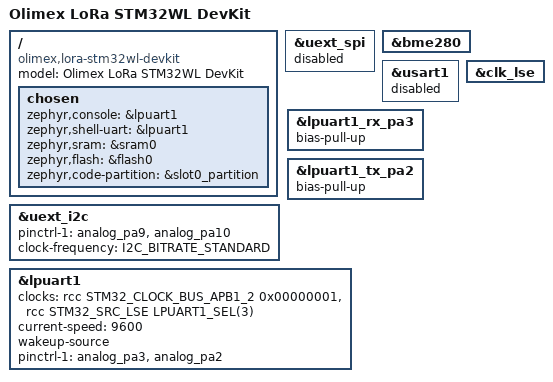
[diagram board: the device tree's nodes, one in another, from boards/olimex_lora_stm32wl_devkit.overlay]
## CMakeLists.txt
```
# SPDX-License-Identifier: Apache-2.0

cmake_minimum_required(VERSION 3.20.0)

find_package(Zephyr REQUIRED HINTS $ENV{ZEPHYR_BASE})
project(helium_meteo)

target_sources(                             app PRIVATE src/main.c)
target_sources_ifdef(CONFIG_SETTINGS        app PRIVATE src/nvm.c)
target_sources_ifdef(CONFIG_SHELL           app PRIVATE src/shell.c)
```

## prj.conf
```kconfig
# SPDX-License-Identifier: Apache-2.0

CONFIG_LOG=y
CONFIG_SPI=y
CONFIG_GPIO=y
CONFIG_LORA=y
CONFIG_LORA_STM32WL_SUBGHZ_RADIO=y
CONFIG_LORAWAN=y
CONFIG_LORAMAC_REGION_EU868=y
CONFIG_LORAWAN_SYSTEM_MAX_RX_ERROR=200
CONFIG_MAIN_STACK_SIZE=2048
CONFIG_SYSTEM_WORKQUEUE_STACK_SIZE=2048
CONFIG_FLASH_MAP=y
CONFIG_FLASH=y
CONFIG_SETTINGS=y
CONFIG_NVS=y

CONFIG_SERIAL=y
CONFIG_CONSOLE=y
CONFIG_UART_CONSOLE=y
CONFIG_UART_LINE_CTRL=y

# Shell
CONFIG_SHELL=y
CONFIG_DATE_SHELL=y
CONFIG_POSIX_TIMERS=y
CONFIG_SHELL_BACKEND_DUMMY=y

# Logging
CONFIG_LOG_PROCESS_THREAD_STACK_SIZE=1024

# OS
CONFIG_REBOOT=y
CONFIG_HEAP_MEM_POOL_SIZE=2048

# Power
CONFIG_PM=y
CONFIG_PM_DEVICE=y
CONFIG_PM_DEVICE_RUNTIME=y


# BME280 Sensor.
CONFIG_SENSOR=y
CONFIG_SENSOR_SHELL=y
CONFIG_BME280=y
CONFIG_BME280_MODE_FORCED=y
CONFIG_BME280_TEMP_OVER_4X=y
CONFIG_BME280_PRESS_OVER_4X=y
CONFIG_BME280_HUMIDITY_OVER_4X=y
```

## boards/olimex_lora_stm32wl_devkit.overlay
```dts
#include <zephyr/dt-bindings/pinctrl/stm32-pinctrl.h>

/ {
        model = "Olimex LoRa STM32WL DevKit";
        compatible = "olimex,lora-stm32wl-devkit";

        chosen {
                zephyr,console = &lpuart1;
                zephyr,shell-uart = &lpuart1;
                zephyr,sram = &sram0;
                zephyr,flash = &flash0;
                zephyr,code-partition = &slot0_partition;
        };

};

&uext_spi {
	status = "disabled";
};

&bme280 {
	status = "okay";
};

&usart1 {
	status = "disabled";
};

#if 0
&pinctrl {
	powerdown_pa9: powerdown_pa9 {
		pinmux = <STM32_PINMUX('A', 9, GPIO)>;
		output-high;
		bias-disable;
	};
	powerdown_pa10: powerdown_pa10{
		pinmux = <STM32_PINMUX('A', 10, GPIO)>;
		output-high;
		bias-disable;
	};
};
#endif

&uext_i2c {
	pinctrl-1 = <&analog_pa9 &analog_pa10>;
	pinctrl-names = "default", "sleep";
	clock-frequency = <I2C_BITRATE_STANDARD>;

	status = "okay";
};

&lpuart1_rx_pa3 {
	bias-pull-up;
};

&lpuart1_tx_pa2 {
	bias-pull-up;
};

&lpuart1 {
        clocks = <&rcc STM32_CLOCK_BUS_APB1_2 0x00000001>,
                <&rcc STM32_SRC_LSE LPUART1_SEL(3)>;

	current-speed = <9600>;

	wakeup-source;

        /* Configure sleep pinctrl configuration which will be used when
         * device is not configured as wakeup source by the application.
         * This use case is only applicable in PM_DEVICE mode.
         */
        pinctrl-1 = <&analog_pa3 &analog_pa2>;
        pinctrl-names = "default", "sleep";

};


&clk_lse {
	status = "okay";
};
```

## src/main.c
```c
/*
 *
 * SPDX-License-Identifier: Apache-2.0
 */

#include <stdio.h>
#include <stdlib.h>
#include <zephyr/device.h>
#include <zephyr/drivers/sensor.h>
#include <zephyr/drivers/gpio.h>
#include <zephyr/lorawan/lorawan.h>
#include <zephyr/kernel.h>
#include <zephyr/sys/reboot.h>
#include <zephyr/sys/printk.h>
#include <zephyr/pm/device.h>
#include <zephyr/pm/policy.h>


#include "lorawan_config.h"
#if IS_ENABLED(CONFIG_ADC)
#include "battery.h"
#endif
#include "nvm.h"
#if IS_ENABLED(CONFIG_SHELL)
#include "shell.h"
#endif

#define LOG_LEVEL CONFIG_LOG_DEFAULT_LEVEL
#include <zephyr/logging/log.h>
LOG_MODULE_REGISTER(helium_meteo);

/*
 * A build error on this line means your board is unsupported.
 * See the sample documentation for information on how to fix this.
 */
static const struct gpio_dt_spec dt_led0 = GPIO_DT_SPEC_GET(DT_ALIAS(led0), gpios);
static const struct gpio_dt_spec dt_sw0 = GPIO_DT_SPEC_GET(DT_ALIAS(sw0), gpios);
static struct gpio_callback user_button_cb_data;

const struct device *const dev_console = DEVICE_DT_GET(DT_CHOSEN(zephyr_console));


struct s_lorawan_config lorawan_config = {
	.dev_eui = { 0x00, 0x01, 0x02, 0x03, 0x04, 0x05, 0x06, 0x07 },
	.app_eui = { 0x00, 0x01, 0x02, 0x03, 0x04, 0x05, 0x06, 0x07 },
	.app_key = { 0x00, 0x01, 0x02, 0x03, 0x04, 0x05, 0x06, 0x07, 0x08, 0x09, 0x0A, 0x0B, 0x0C, 0x0D, 0x0E, 0x0F },
	.lora_mode = LORAWAN_ACT_OTAA,
	.data_rate = LORAWAN_DR_3,
	.lora_class = LORAWAN_CLASS_A,
	.confirmed_msg = LORAWAN_MSG_UNCONFIRMED,
	.app_port = 2,
	.auto_join = false,
	.send_repeat_time = 3600 / 2,
	/* max join attempt in one join session */
	.join_try_count = 5,
	/* max join sessions before give up and reboot. 20 * 5 = 100 join attempts */
	.max_join_retry_sessions_count = 20,
	/* max join session interval in sec */
	.join_try_interval = 300,
	.max_inactive_time_window = 2 * 3600,
	.max_failed_msg = 120,
};

struct s_status lorawan_status = {
	.joined = false,
	.msgs_sent = 0,
	.msgs_failed = 0,
	.msgs_failed_total = 0,
	.join_retry_sessions_count = 0,
};

struct s_meteo_data meteo_data;
char *data_ptr = (char*)&meteo_data;

#define LORA_JOIN_THREAD_STACK_SIZE 1500
#define LORA_JOIN_THREAD_PRIORITY 10
K_KERNEL_STACK_MEMBER(lora_join_thread_stack, LORA_JOIN_THREAD_STACK_SIZE);

struct s_helium_meteo_ctx {
	const struct device *lora_dev;
	const struct device *meteo_dev;
	struct k_timer send_timer;
	struct k_timer lora_join_timer;
	struct k_thread thread;
	struct k_sem lora_join_sem;
};

struct s_helium_meteo_ctx g_ctx;

enum lorawan_state_e {
	NOT_JOINED,
	JOINED,
};

/* Event queue. */

enum evt_t {
	EV_TIMER,
	EV_BUTTON,
	EV_SEND_DATA,
};

struct app_evt_t {
	enum evt_t event_type;
};

K_MSGQ_DEFINE(event_msgq, sizeof(struct app_evt_t), 10, 1);


static void update_send_timer(struct s_helium_meteo_ctx *ctx)
{
	uint32_t time = lorawan_config.send_repeat_time;

	if (time) {
		LOG_INF("Send interval timer start for %d sec", time);
		k_timer_start(&ctx->send_timer,
				K_SECONDS(time),
				K_SECONDS(time));
	}
}

static void send_timer_handler(struct k_timer *timer)
{
	struct app_evt_t ev;

	LOG_INF("Timer handler");

	ev.event_type = EV_TIMER;
	while (k_msgq_put(&event_msgq, &ev, K_NO_WAIT) != 0) {
		/* message queue is full: purge old data & try again */
		k_msgq_purge(&event_msgq);
	}
}

static void user_button_pressed(const struct device *dev, struct gpio_callback *cb,
                    uint32_t pins)
{
	struct app_evt_t ev;

	LOG_INF("Button handler");

	ev.event_type = EV_BUTTON;
	while (k_msgq_put(&event_msgq, &ev, K_NO_WAIT) != 0) {
		/* message queue is full: purge old data & try again */
		k_msgq_purge(&event_msgq);
	}
}


static int init_buttons(void)
{
	int err;

	if (!dt_sw0.port) {
		LOG_INF("User button not available");
		return -ENODEV;
	}
	if (!device_is_ready(dt_sw0.port)) {
		LOG_ERR("User button device not ready");
		return -ENODEV;
	}
	err = gpio_pin_configure_dt(&dt_sw0, GPIO_INPUT);
	if (err) {
		LOG_ERR("failed to configure user button gpio: %d", err);
		return err;
	}
	err = gpio_pin_interrupt_configure_dt(&dt_sw0, GPIO_INT_EDGE_TO_ACTIVE);
	if (err) {
		LOG_ERR("failed to configure user button gpio: %d", err);
		return err;
	}
	gpio_init_callback(&user_button_cb_data, user_button_pressed, BIT(dt_sw0.pin));
	gpio_add_callback(dt_sw0.port, &user_button_cb_data);

	return err;
}

static int init_leds(void)
{
	int err = 0;

	if (!dt_led0.port) {
		LOG_INF("LED0 not available");
		return -ENODEV;
	}
	if (!device_is_ready(dt_led0.port)) {
		LOG_ERR("LED0 device not ready");
		return -ENODEV;
	}
	/* Init led as output and turn it off */
	err = gpio_pin_configure_dt(&dt_led0, GPIO_OUTPUT_INACTIVE);
	if (err) {
		LOG_ERR("failed to configure LED0 gpio: %d", err);
		return err;
	}
	/* This is required to reach low-power modes. */
	err = gpio_pin_configure_dt(&dt_led0, GPIO_DISCONNECTED);

	return err;
}

static void led_enable(const struct gpio_dt_spec *led, int enable)
{
	if (led->port) {
		gpio_pin_set_dt(led, enable);
	}
}

static void dl_callback(uint8_t port, uint8_t flags, int16_t rssi, int8_t snr, uint8_t len,
			const uint8_t *data)
{
	LOG_INF("Port %d, Flags %x, RSSI %ddB, SNR %ddBm", port, flags, rssi, snr);
	if (data) {
		LOG_HEXDUMP_INF(data, len, "Payload: ");
	}
}

static struct lorawan_downlink_cb downlink_cb = {
	.port = LW_RECV_PORT_ANY,
	.cb = dl_callback
};

static void lorwan_datarate_changed(enum lorawan_datarate dr)
{
	uint8_t unused, max_size;

	lorawan_get_payload_sizes(&unused, &max_size);
	LOG_INF("New Datarate: DR_%d, Max Payload %d", dr, max_size);
}

static int init_meteo(struct s_helium_meteo_ctx *ctx)
{
        ctx->meteo_dev = DEVICE_DT_GET_ANY(bosch_bme280);

        if (ctx->meteo_dev == NULL) {
                /* No such node, or the node does not have status "okay". */
                LOG_ERR("No BME280 device found.\n");
                return -ENODEV;
        }

        if (!device_is_ready(ctx->meteo_dev)) {
                LOG_ERR("Device \"%s\" is not ready; "
                       "check the driver initialization logs for errors.\n",
                       ctx->meteo_dev->name);
                return -EBUSY;
        }

        LOG_INF("Found device \"%s\", getting sensor data\n", ctx->meteo_dev->name);

        return 0;
}

static const char *lorawan_state_str(enum lorawan_state_e state)
{
	switch(state) {
	case NOT_JOINED:
		return "NOT_JOINED";
	case JOINED:
		return "JOINED";
	}

	return "UNKNOWN";
}

static void lorawan_state(struct s_helium_meteo_ctx *ctx, enum lorawan_state_e state)
{
	uint32_t join_try_interval_sec = lorawan_config.join_try_interval;

	LOG_INF("LoraWAN state set to: %s", lorawan_state_str(state));

	switch (state) {
	case NOT_JOINED:
		if (!lorawan_config.auto_join) {
			LOG_WRN("Join is not enabled");
			break;
		}
		lorawan_status.joined = false;
		LOG_INF("Lora join timer start for %d sec", join_try_interval_sec);
		k_timer_start(&ctx->lora_join_timer, K_SECONDS(join_try_interval_sec),
				K_NO_WAIT);
		k_sem_give(&ctx->lora_join_sem);
		break;

	case JOINED:
		lorawan_status.joined = true;
		lorawan_status.join_retry_sessions_count = 0;
		LOG_INF("Stop Lora join retry timer");
		k_timer_stop(&ctx->lora_join_timer);
		break;

	default:
		LOG_ERR("Unknown LoraWAN state");
		break;
	} /* switch */
}

static void lora_join_timer_handler(struct k_timer *timer)
{
	struct s_helium_meteo_ctx *ctx =
		CONTAINER_OF(timer, struct s_helium_meteo_ctx, lora_join_timer);

	LOG_INF("LoraWAN join timer handler");

	/* If not joined within 'join_try_interval', try again */
	if (!lorawan_status.joined) {
		lorawan_state(ctx, NOT_JOINED);
	}
}

static int join_lora(struct s_helium_meteo_ctx *ctx)
{
	struct pm_policy_latency_request req;
	struct lorawan_join_config join_cfg;
	int retry = lorawan_config.join_try_count;
	int ret = 0;

	pm_policy_latency_request_add(&req, 3);

	join_cfg.mode = lorawan_config.lora_mode;
	join_cfg.dev_eui = lorawan_config.dev_eui;
	join_cfg.otaa.join_eui = lorawan_config.app_eui;
	join_cfg.otaa.app_key = lorawan_config.app_key;
	join_cfg.otaa.nwk_key = lorawan_config.app_key;

	if (lorawan_config.auto_join) {
		while (retry--) {
			LOG_INF("Joining network over OTAA. Attempt: %d",
					lorawan_config.join_try_count - retry);
			ret = lorawan_join(&join_cfg);
			if (ret == 0) {
				break;
			}
			LOG_ERR("lorawan_join_network failed: %d", ret);
			k_sleep(K_SECONDS(15));
		}

		if (ret == 0) {
			lorawan_state(ctx, JOINED);
		}
	}

	pm_policy_latency_request_remove(&req);

	return ret;
}

static void lora_join_thread(struct s_helium_meteo_ctx *ctx)
{
	uint16_t retry_count_conf = lorawan_config.max_join_retry_sessions_count;
	int err;

	while (1) {
		k_sem_take(&ctx->lora_join_sem, K_FOREVER);
		err = join_lora(ctx);
		if (err) {
			lorawan_status.join_retry_sessions_count++;
		}

		if (lorawan_status.join_retry_sessions_count > retry_count_conf) {
			LOG_ERR("Reboot in 30sec");
			k_sleep(K_SECONDS(30));
			sys_reboot(SYS_REBOOT_WARM);
			return; /* won't reach this */
		}
	}
}

static int init_lora(struct s_helium_meteo_ctx *ctx)
{
	const struct device *lora_dev;
	int ret;

	lora_dev = DEVICE_DT_GET(DT_ALIAS(lora0));
	if (!device_is_ready(lora_dev)) {
		LOG_ERR("%s: device not ready.", lora_dev->name);
		return -ENODEV;
	}

	ret = lorawan_start();
	if (ret < 0) {
		LOG_ERR("lorawan_start failed: %d", ret);
		return ret;
	}

	lorawan_register_downlink_callback(&downlink_cb);
	lorawan_register_dr_changed_callback(lorwan_datarate_changed);
	lorawan_set_datarate(lorawan_config.data_rate);

	k_sem_init(&ctx->lora_join_sem, 0, K_SEM_MAX_LIMIT);

	k_thread_create(&ctx->thread, lora_join_thread_stack,
			K_THREAD_STACK_SIZEOF(lora_join_thread_stack),
			(k_thread_entry_t)lora_join_thread, ctx, NULL, NULL,
			K_PRIO_PREEMPT(LORA_JOIN_THREAD_PRIORITY), 0,
			K_SECONDS(1));

	k_thread_name_set(&ctx->thread, "lora_join");

	/* make initial join */
	lorawan_state(ctx, NOT_JOINED);

	return 0;
}

static void init_timers(struct s_helium_meteo_ctx *ctx)
{
	k_timer_init(&ctx->send_timer, send_timer_handler, NULL);
	k_timer_init(&ctx->lora_join_timer, lora_join_timer_handler, NULL);

	update_send_timer(ctx);
}

static void send_event(struct s_helium_meteo_ctx *ctx)
{
	struct app_evt_t ev;

	if (!lorawan_status.joined) {
		LOG_WRN("Not joined");
		return;
	}

	if (!lorawan_config.send_repeat_time) {
		LOG_WRN("Periodic send is disabled");
		return;
	}

	ev.event_type = EV_SEND_DATA;
	while (k_msgq_put(&event_msgq, &ev, K_NO_WAIT) != 0) {
		/* message queue is full: purge old data & try again */
		k_msgq_purge(&event_msgq);
	}
}

static void lora_send_msg(struct s_helium_meteo_ctx *ctx)
{
	struct pm_policy_latency_request req;
	uint8_t msg_type = lorawan_config.confirmed_msg;
	uint32_t max_failed_msgs = lorawan_config.max_failed_msg;
	int err;

	if (!lorawan_status.joined) {
		LOG_WRN("Not joined");
		return;
	}

	pm_policy_latency_request_add(&req, 3);

	memset(data_ptr, 0, sizeof(struct s_meteo_data));

	if (ctx->meteo_dev != NULL) {
		struct sensor_value temperature, press, humidity;

		err = sensor_sample_fetch(ctx->meteo_dev);
		if (err != 0)
			LOG_ERR("sensor_sample_fetch failed: %d", err);

		err = sensor_channel_get(ctx->meteo_dev, SENSOR_CHAN_AMBIENT_TEMP, &temperature);
		if (err != 0)
			LOG_ERR("get temperature failed: %d", err);
		err = sensor_channel_get(ctx->meteo_dev, SENSOR_CHAN_PRESS, &press);
		if (err != 0)
			LOG_ERR("get pressure failed: %d", err);
		err = sensor_channel_get(ctx->meteo_dev, SENSOR_CHAN_HUMIDITY, &humidity);
		if (err != 0)
			LOG_ERR("get humidity failed: %d", err);

		LOG_INF("meteo: %d Cel ; %d %%RH\n", temperature.val1, humidity.val1);

		/* Celsius to milliKelvin. */
		meteo_data.temp_mK = (temperature.val1 + 273) * 1000 + (temperature.val2 / 1000 + 150);
		/* KPa to Pa */
		meteo_data.pressure_Pa = press.val1 * 1000;
		/* Both Zephyr and Helium Meteo in percents. */
		meteo_data.humidity_percent = humidity.val1;
	}

#if IS_ENABLED(CONFIG_ADC)
	int batt_mV;
	err = read_battery(&batt_mV);
	if (err == 0) {
		meteo_data.battery_mV = (uint16_t)batt_mV;
	}
#endif

	LOG_HEXDUMP_DBG(data_ptr, sizeof(struct s_meteo_data),
			"meteo_data");

	/* Send at least one confirmed msg on every 10 to check connectivity */
	if (msg_type == LORAWAN_MSG_UNCONFIRMED &&
			!(lorawan_status.msgs_sent % 10)) {
		msg_type = LORAWAN_MSG_CONFIRMED;
	}

	LOG_INF("Lora send -------------->");

	led_enable(&dt_led0, 1);
	err = lorawan_send(lorawan_config.app_port,
			data_ptr, sizeof(struct s_meteo_data),
			msg_type);
	if (err < 0) {
		//TODO: make special LED pattern in this case
		lorawan_status.msgs_failed++;
		lorawan_status.msgs_failed_total++;
		LOG_ERR("lorawan_send failed: %d", err);
	} else {
		lorawan_status.msgs_sent++;
		lorawan_status.msgs_failed = 0;
		LOG_INF("Data sent!");
	}
	led_enable(&dt_led0, 0);

	if (lorawan_status.msgs_failed > max_failed_msgs) {
		LOG_ERR("Too many failed msgs: Try to re-join.");
		lorawan_state(ctx, NOT_JOINED);
		k_sem_give(&ctx->lora_join_sem);
	}
	pm_policy_latency_request_remove(&req);
}

#if IS_ENABLED(CONFIG_SHELL)
static void shell_cb(enum shell_cmd_event event, void *data) {
	struct s_helium_meteo_ctx *ctx = (struct s_helium_meteo_ctx *)data;

	switch (event) {
	case SHELL_CMD_SEND_TIMER:
		update_send_timer(ctx);
		break;
	case SHELL_CMD_SEND_TIMER_GET:
		time_t time_st_left = k_timer_remaining_get(&ctx->send_timer);
		LOG_INF("Send timer %lld sec left", time_st_left / 1000);
		break;
	default:
		LOG_WRN("Unknown shell cmd event");
		break;
	} /* switch */
}
#endif

static void app_evt_handler(struct app_evt_t *ev, struct s_helium_meteo_ctx *ctx)
{
	switch (ev->event_type) {
	case EV_TIMER:
		LOG_INF("Event Timer");
		send_event(ctx);
		update_send_timer(ctx);
		break;

	case EV_BUTTON:
		LOG_INF("Event Button");
		send_event(ctx);
		break;

	case EV_SEND_DATA:
		lora_send_msg(ctx);
		break;
	default:
		LOG_ERR("Unknown event");
		break;

	} /* switch */
}

int main(void)
{
	struct s_helium_meteo_ctx *ctx = &g_ctx;
	int ret;

	ret = init_leds();
	if (ret) {
		return ret;
	}

	ret = init_buttons();
	if (ret) {
		return ret;
	}

#if IS_ENABLED(CONFIG_SETTINGS)
	ret = load_config();
	if (ret) {
		goto fail;
	}
#endif

	init_timers(ctx);

	ret = init_meteo(ctx);
	if (ret) {
		goto fail;
	}

#if IS_ENABLED(CONFIG_SHELL)
	if (device_is_ready(dev_console) && pm_device_wakeup_is_capable(dev_console)) {
		ret = pm_device_wakeup_enable(dev_console, true);
		if (!ret) {
			printk("Could not enable wakeup source\n");
		} else {
			printk("Wakeup source enable ok\n");
		}
	}

	ret = init_shell();
	if (ret) {
		goto fail;
	}

	shell_register_cb(shell_cb, ctx);
#endif

	ret = init_lora(ctx);
	if (ret) {
		LOG_ERR("Rebooting in 30 sec.");
		k_sleep(K_SECONDS(30));
		sys_reboot(SYS_REBOOT_WARM);
		goto fail;
	}

	while (true) {
		struct app_evt_t ev;

		LOG_INF("Waiting for events...");

		k_msgq_get(&event_msgq, &ev, K_FOREVER);
		app_evt_handler(&ev, ctx);
	}

fail:
	while (true) {
		if (dt_led0.port) {
			gpio_pin_set_dt(&dt_led0, 0);
			k_sleep(K_MSEC(250));
			gpio_pin_set_dt(&dt_led0, 1);
		}
		k_sleep(K_SECONDS(1));
	}

	return 0;
}
```

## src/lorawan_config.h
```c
/*
 *
 */

#ifndef __LORAWAN_CONFIG_H__
#define __LORAWAN_CONFIG_H__

#include <stdio.h>
#include <zephyr/lorawan/lorawan.h>

struct s_lorawan_config
{
	/* OTAA Device EUI MSB */
	char dev_eui[8];
	/* OTAA Application EUI MSB */
	uint8_t app_eui[8];
	/* OTAA Application Key MSB */
	uint8_t app_key[16];
	/* LoRaWAN activation mode */
	uint8_t lora_mode;
	/* Data rate (depnends on Region) */
	uint8_t data_rate;
	/* LoRaWAN class */
	uint8_t lora_class;
	/* Type of messages: confirmed or un-confirmed */
	uint8_t confirmed_msg;
	/* Data port to send data */
	uint8_t app_port;
	/* Flag if node joins automatically after reboot */
	bool auto_join;
	/* Send repeat time in seconds */
	uint32_t send_repeat_time;
	/* Max attempt to join network */
	uint8_t join_try_count;
	/* Max LoraWAN join sessions retry count before reboot */
	uint16_t max_join_retry_sessions_count;
	/* Max LoraWAN join window interval in seconds */
	uint32_t join_try_interval;
	/* Max time window of no ack'd msg received before re-join in seconds */
	uint32_t max_inactive_time_window;
	/* Number of failed message before re-join */
	uint32_t max_failed_msg;
};

extern struct s_lorawan_config lorawan_config;

struct s_meteo_data
{
	uint32_t temp_mK;
	uint32_t pressure_Pa;
	uint8_t humidity_percent;
	uint16_t battery_mV;
} __packed;

struct s_status {
	bool joined;
	bool delayed_active;
	uint32_t msgs_sent;
	uint32_t msgs_failed;
	uint32_t msgs_failed_total;
	uint16_t join_retry_sessions_count;
};

extern struct s_status lorawan_status;

#endif /* __LORAWAN_CONFIG_H__ */
```

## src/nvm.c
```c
#include <stdio.h>
#include <zephyr/settings/settings.h>

#include "lorawan_config.h"

#define LOG_LEVEL CONFIG_LOG_DEFAULT_LEVEL
#include <zephyr/logging/log.h>
LOG_MODULE_REGISTER(helium_meteo_nvm);

#define HELIUM_METEO_SETTINGS_BASE "helium_meteo/nvm"

struct hm_nvm_setting_descr {
	const char *name;
	const char *setting_name;
	size_t size;
	off_t offset;
};

#define HM_NVM_SETTING_DESCR(_member) \
	{									\
		.name = STRINGIFY(_member),					\
		.setting_name =							\
			HELIUM_METEO_SETTINGS_BASE "/" STRINGIFY(_member),	\
		.offset = offsetof(struct s_lorawan_config, _member),			\
		.size = sizeof(((struct s_lorawan_config *)0)->_member),		\
	}

static const struct hm_nvm_setting_descr hm_nvm_setting_descriptors[] = {
	HM_NVM_SETTING_DESCR(dev_eui),
	HM_NVM_SETTING_DESCR(app_eui),
	HM_NVM_SETTING_DESCR(app_key),
	HM_NVM_SETTING_DESCR(confirmed_msg),
	HM_NVM_SETTING_DESCR(auto_join),
	HM_NVM_SETTING_DESCR(send_repeat_time),
};

void hm_lorawan_nvm_save_settings(const char *name)
{
	LOG_DBG("Saving LoRaWAN settings");

	struct s_lorawan_config *nvm = (void *)&lorawan_config;

	for (uint32_t i = 0; i < ARRAY_SIZE(hm_nvm_setting_descriptors); i++) {
		const struct hm_nvm_setting_descr *descr =
			&hm_nvm_setting_descriptors[i];

		if (!strncmp(descr->name, name, strlen(name))) {
			LOG_DBG("Saving configuration %s", descr->setting_name);
			int err = settings_save_one(descr->setting_name,
						(char *)nvm + descr->offset,
						descr->size);
			if (err) {
				LOG_ERR("Could not save settings %s, err: %d",
					descr->name, err);
			}
		}
	}
}

static int hm_load_setting(void *tgt, size_t tgt_size,
			const char *key, size_t len,
			settings_read_cb read_cb, void *cb_arg)
{
	if (len != tgt_size) {
		LOG_ERR("Can't load '%s' state, size mismatch.",
			key);
		return -EINVAL;
	}

	if (!tgt) {
		LOG_ERR("Can't load '%s' state, no target.",
			key);
		return -EINVAL;
	}

	if (read_cb(cb_arg, tgt, len) != len) {
		LOG_ERR("Can't load '%s' state, short read.",
			key);
		return -EINVAL;
	}

	return 0;
}

static int hm_on_setting_loaded(const char *key, size_t len,
			   settings_read_cb read_cb,
			   void *cb_arg, void *param)
{
	int err = 0;
	struct s_lorawan_config *nvm = param;

	LOG_DBG("Key: %s", key);

	for (uint32_t i = 0; i < ARRAY_SIZE(hm_nvm_setting_descriptors); i++) {
		const struct hm_nvm_setting_descr *descr =
			&hm_nvm_setting_descriptors[i];

		LOG_DBG("key: %s, desc->name: %s", key, descr->name);
		if (strcmp(descr->name, key) == 0) {
			err = hm_load_setting((char *)nvm + descr->offset,
				descr->size, key, len, read_cb, cb_arg);
			if (err) {
				LOG_ERR("Could not read setting %s", descr->name);
			}
			return err;
		}
	}

	LOG_WRN("Unknown LoRaWAN setting: %s", key);

	return err;
}

int config_nvm_data_restore(void)
{
	int err = 0;

	LOG_DBG("Restoring helium_meteo config settings");

	err = settings_load_subtree_direct(HELIUM_METEO_SETTINGS_BASE,
					   hm_on_setting_loaded,
					   (void *)&lorawan_config);
	if (err) {
		LOG_ERR("Could not load config settings, err %d", err);
		return err;
	}

	LOG_DBG("config setings restored");

	return 0;
}

int load_config(void)
{
	int err = 0;

	if (!IS_ENABLED(CONFIG_LORAWAN_NVM_NONE)) {
		err = settings_subsys_init();
		if (err) {
			LOG_ERR("Could not init settings, err: %d", err);
			return err;
		}
		err = config_nvm_data_restore();
		if (err) {
			LOG_ERR("Could not restore settings, err: %d", err);
			return err;
		}
	}

	return err;
}
```

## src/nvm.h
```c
/*
 *
 * SPDX-License-Identifier: Apache-2.0
 */

#ifndef __HELIUM_METEO_NVM_H__
#define __HELIUM_METEO_NVM_H__

void hm_lorawan_nvm_save_settings(const char *name);

int load_config(void);

#endif /* __HELIUM_METEO_NVM_H__ */
```

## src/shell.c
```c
/*
 *
 * SPDX-License-Identifier: Apache-2.0
 */

#include <stdlib.h>
#include <zephyr/device.h>
#include <zephyr/kernel.h>
#include <zephyr/sys/reboot.h>
#include <zephyr/shell/shell.h>
#include <version.h>
#include <zephyr/posix/time.h>
#include <zephyr/sys/timeutil.h>

#include "lorawan_config.h"
#if IS_ENABLED(CONFIG_ADC)
#include "battery.h"
#endif
#include "nvm.h"
#include "shell.h"

#define LOG_LEVEL CONFIG_LOG_DEFAULT_LEVEL
#include <zephyr/logging/log.h>
LOG_MODULE_REGISTER(helium_meteo_shell);

struct shell_ctx_s {
	shell_cmd_cb_t shell_cb;
	void *data;
} shell_ctx = { .shell_cb = NULL, .data = NULL };

void shell_register_cb(shell_cmd_cb_t cb, void *data)
{
	shell_ctx.shell_cb = cb;
	shell_ctx.data = data;
}

size_t lorawan_hex2bin(const char *hex, size_t hexlen, uint8_t *buf, size_t buflen)
{
	uint8_t dec;

	if (buflen < hexlen / 2 + hexlen % 2) {
		return 0;
	}

	/* If hexlen is uneven, don't parse the input. */
	if (hexlen % 2) {
		return 0;
	}

	/* regular hex conversion */
	for (size_t i = 0; i < hexlen / 2; i++) {
		if (char2hex(hex[2 * i], &dec) < 0) {
			return 0;
		}
		buf[i] = dec << 4;

		if (char2hex(hex[2 * i + 1], &dec) < 0) {
			return 0;
		}
		buf[i] += dec;
	}

	return hexlen / 2;
}

#define DEFAULT_PASSWORD "zephyr"

static void login_init(void)
{
	LOG_INF("Welcome to helium meteo");
	if (!CONFIG_SHELL_CMD_ROOT[0]) {
		shell_set_root_cmd("login");
	}
}

static int check_passwd(char *passwd)
{
	/* example only -- not recommended for production use */
	return strcmp(passwd, DEFAULT_PASSWORD);
}

static int cmd_login(const struct shell *shell, size_t argc, char **argv)
{
	static uint32_t attempts;

	if (check_passwd(argv[1]) != 0) {
		shell_error(shell, "Incorrect password!");
		attempts++;
		if (attempts > 3) {
			k_sleep(K_SECONDS(attempts));
		}
		return -EINVAL;
	}

	/* clear history so password not visible there */
	z_shell_history_purge(shell->history);
	shell_obscure_set(shell, false);
	shell_set_root_cmd(NULL);
	shell_prompt_change(shell, "uart:~$ ");
	shell_print(shell, "Welcome to helium meteo\n");
	shell_print(shell, "Hit tab for help.\n");
	attempts = 0;
	return 0;
}

static int cmd_logout(const struct shell *shell, size_t argc, char **argv)
{
	shell_set_root_cmd("login");
	shell_obscure_set(shell, true);
	shell_prompt_change(shell, "login: ");
	shell_print(shell, "\n");
	return 0;
}

static int cmd_config(const struct shell *shell, size_t argc, char **argv)
{
	ARG_UNUSED(argc);
	ARG_UNUSED(argv);
	int i;

	shell_print(shell, "Device config:");
	shell_print(shell, "  Helium meteo: %s, %s %s", STRINGIFY(BUILD_VERSION),
			__DATE__, __TIME__);

	shell_fprintf(shell, SHELL_NORMAL, "  Dev EUI          ");
	for (i = 0; i < sizeof(lorawan_config.dev_eui); i++) {
		shell_fprintf(shell, SHELL_NORMAL, "%02X", lorawan_config.dev_eui[i] & 0xFF);
	}
	shell_print(shell, "");

	shell_fprintf(shell, SHELL_NORMAL, "  APP EUI          ");
	for (i = 0; i < sizeof(lorawan_config.app_eui); i++) {
		shell_fprintf(shell, SHELL_NORMAL, "%02X", lorawan_config.app_eui[i] & 0xFF);
	}
	shell_print(shell, "");

	shell_fprintf(shell, SHELL_NORMAL, "  APP key          ");
	for (i = 0; i < sizeof(lorawan_config.app_key); i++) {
		shell_fprintf(shell, SHELL_NORMAL, "%02X", lorawan_config.app_key[i] & 0xFF);
	}
	shell_print(shell, "");

	shell_print(shell, "  Auto join        %s", lorawan_config.auto_join ? "true" : "false");
	shell_print(shell, "  Data rate/DR+    %d", lorawan_config.data_rate);
	shell_print(shell, "  Confirmed msgs   %s", lorawan_config.confirmed_msg ? "true" : "false");
	shell_print(shell, "  Max failed msgs  %d", lorawan_config.max_failed_msg);
	shell_print(shell, "  Inactive window  %d sec", lorawan_config.max_inactive_time_window);
	shell_print(shell, "  Send interval    %d sec", lorawan_config.send_repeat_time);

	return 0;
}
SHELL_CMD_ARG_REGISTER(config, NULL, "Show helium_meteo config", cmd_config, 1, 0);

static int cmd_status(const struct shell *shell, size_t argc, char **argv)
{
	ARG_UNUSED(argc);
	ARG_UNUSED(argv);

	struct timespec tp;
	struct tm tm;
	uint16_t join_retry_sessions_count = lorawan_status.join_retry_sessions_count;

	clock_gettime(CLOCK_REALTIME, &tp);
	gmtime_r(&tp.tv_sec, &tm);

	shell_print(shell, "Device status:");
	shell_print(shell, "  joined           %s", lorawan_status.joined ? "true" : "false");
	shell_print(shell, "  delayed active   %s", lorawan_status.delayed_active ? "true" : "false");
	shell_print(shell, "  messages sent    %d", lorawan_status.msgs_sent);
	shell_print(shell, "  messages failed  %d", lorawan_status.msgs_failed);
	shell_print(shell, "  msg failed total %d", lorawan_status.msgs_failed_total);
	shell_print(shell, "  Join retry sess  %d", join_retry_sessions_count);
	shell_print(shell, "  Uptime           %04d-%02u-%02u %02u:%02u:%02u",
		    tm.tm_year - 70,
		    tm.tm_mon,
		    tm.tm_mday - 1,
		    tm.tm_hour,
		    tm.tm_min,
		    tm.tm_sec);

	return 0;
}
SHELL_CMD_ARG_REGISTER(status, NULL, "Show helium_meteo status", cmd_status, 1, 0);

#if IS_ENABLED(CONFIG_ADC)
static int cmd_battery(const struct shell *shell, size_t argc, char **argv)
{
	uint16_t batt_pptt;
	int batt_mV;
	int err;

	ARG_UNUSED(argc);
	ARG_UNUSED(argv);

	err = read_battery(&batt_mV);
	if (err < 0) {
		return err;
	}

	batt_pptt = battery_level_pptt(batt_mV, levels);
	shell_print(shell, "Battery: %d mV, %u %%", batt_mV, batt_pptt / 100);

	return 0;
}
SHELL_CMD_ARG_REGISTER(battery, NULL, "Show battery status", cmd_battery, 1, 0);
#endif

static int cmd_reboot(const struct shell *shell, size_t argc, char **argv)
{
	ARG_UNUSED(argc);
	ARG_UNUSED(argv);

	shell_print(shell, "Reboot...");
	sys_reboot(SYS_REBOOT_WARM);

	return 0;
}
SHELL_CMD_ARG_REGISTER(reboot, NULL, "Reboot deice", cmd_reboot, 1, 0);

static int shell_lorawan_hexdump(const struct shell *shell, char *buf, size_t len, const char *label)
{
	shell_fprintf(shell, SHELL_NORMAL, "%s", label);
	for (int i = 0; i < len; i++) {
		shell_fprintf(shell, SHELL_NORMAL, "%02X", (unsigned char)buf[i] & 0xFFu);
	}
	shell_print(shell, "");

	return 0;
}

static int cmd_lorawan_keys(const struct shell *shell, size_t argc, char **argv)
{
	bool save = false;
	size_t len;
	uint8_t buf[16];

	if (argc < 2) {
		if (!strncmp(argv[0], "dev_eui", strlen("dev_eui"))) {
			shell_lorawan_hexdump(shell, lorawan_config.dev_eui,
					sizeof(lorawan_config.dev_eui), "dev_eui ");
		}
		else if (!strncmp(argv[0], "app_eui", strlen("app_eui"))) {
			shell_lorawan_hexdump(shell, lorawan_config.app_eui,
					sizeof(lorawan_config.app_eui), "app_eui ");
		}
		else if (!strncmp(argv[0], "app_key", strlen("app_key"))) {
			shell_lorawan_hexdump(shell, lorawan_config.app_key,
					sizeof(lorawan_config.app_key), "app_key ");
		}
	} else {
		if (!strncmp(argv[0], "dev_eui", strlen("dev_eui"))) {
			len = lorawan_hex2bin(argv[1], strlen(argv[1]), buf, 8);
			if (len != 8) {
				LOG_WRN("Not enough or invalid characters, len: %d", len);
				return -EINVAL;
			}
			LOG_HEXDUMP_DBG(buf, len, "dev_eui: ");
			memcpy(lorawan_config.dev_eui, buf, 8);
			save = true;
		}
		else if (!strncmp(argv[0], "app_eui", strlen("app_eui"))) {
			len = lorawan_hex2bin(argv[1], strlen(argv[1]), buf, 8);
			if (len != 8) {
				LOG_WRN("Not enough or invalid characters, len: %d", len);
				return -EINVAL;
			}
			LOG_HEXDUMP_DBG(buf, len, "app_eui: ");
			memcpy(lorawan_config.app_eui, buf, 8);
			save = true;
		}
		else if (!strncmp(argv[0], "app_key", strlen("app_key"))) {
			len = lorawan_hex2bin(argv[1], strlen(argv[1]), buf, 16);
			if (len != 16) {
				LOG_WRN("Not enough or invalid characters, len: %d", len);
				return -EINVAL;
			}
			LOG_HEXDUMP_DBG(buf, len, "app_key: ");
			memcpy(lorawan_config.app_key, buf, 16);
			save = true;
		}
	}

#if IS_ENABLED(CONFIG_SETTINGS)
	if (save) {
		hm_lorawan_nvm_save_settings(argv[0]);
	}
#endif

	return 0;
}

static int cmd_auto_join(const struct shell *shell, size_t argc, char **argv)
{
	bool save = false;

	if (argc < 2) {
		shell_print(shell, "%s", lorawan_config.auto_join ? "true" : "false");
	} else {
		if (!strncmp(argv[1], "true", strlen("true"))) {
			lorawan_config.auto_join = true;
			save = true;
		}
		if (!strncmp(argv[1], "false", strlen("false"))) {
			lorawan_config.auto_join = false;
			save = true;
		}

		if (save) {
#if IS_ENABLED(CONFIG_SETTINGS)
			hm_lorawan_nvm_save_settings("auto_join");
#endif
		} else {
			shell_print(shell, "Invalid input: valid are true/false");
		}
	}

	return 0;
}

static int cmd_confirmed_msg(const struct shell *shell, size_t argc, char **argv)
{
	bool save = false;

	if (argc < 2) {
		shell_print(shell, "%s", lorawan_config.confirmed_msg ? "true" : "false");
	} else {
		if (!strncmp(argv[1], "true", strlen("true"))) {
			lorawan_config.confirmed_msg = LORAWAN_MSG_CONFIRMED;
			save = true;
		}
		if (!strncmp(argv[1], "false", strlen("false"))) {
			lorawan_config.confirmed_msg = LORAWAN_MSG_UNCONFIRMED;
			save = true;
		}
#if IS_ENABLED(CONFIG_SETTINGS)
		if (save) {
			hm_lorawan_nvm_save_settings("confirmed_msg");
		}
#endif
	}

	return 0;
}

static int cmd_send_interval(const struct shell *shell, size_t argc, char **argv)
{
	if (argc < 2) {
		shell_print(shell, "%u sec", lorawan_config.send_repeat_time);
		if (shell_ctx.shell_cb) {
			shell_ctx.shell_cb(SHELL_CMD_SEND_TIMER_GET, shell_ctx.data);
		}
	} else {
		lorawan_config.send_repeat_time = atoi(argv[1]);
#if IS_ENABLED(CONFIG_SETTINGS)
		hm_lorawan_nvm_save_settings("send_repeat_time");
#endif
		if (shell_ctx.shell_cb) {
			shell_ctx.shell_cb(SHELL_CMD_SEND_TIMER, shell_ctx.data);
		}
	}

	return 0;
}

#define HELP_DEV_EUI "Get/set dev_eui [0011223344556677]"
#define HELP_APP_EUI "Get/set app_eui [0011223344556677]"
#define HELP_APP_KEY "get/set app_key [00112233445566778899aabbccddeeff]"
#define HELP_AUTO_JOIN "Auto join true/false"
#define HELP_CONFIRMED_MSG "Confirmed messages true/false"
#define HELP_SEND_INTERVAL "Send interval in seconds"

SHELL_STATIC_SUBCMD_SET_CREATE(sub_lorawan,
	SHELL_CMD_ARG(dev_eui, NULL, HELP_DEV_EUI, cmd_lorawan_keys, 1, 1),
	SHELL_CMD_ARG(app_eui, NULL, HELP_APP_EUI, cmd_lorawan_keys, 1, 1),
	SHELL_CMD_ARG(app_key, NULL, HELP_APP_KEY, cmd_lorawan_keys, 1, 1),
	SHELL_CMD_ARG(auto_join, NULL, HELP_AUTO_JOIN, cmd_auto_join, 1, 1),
	SHELL_CMD_ARG(confirmed_msg, NULL, HELP_CONFIRMED_MSG, cmd_confirmed_msg, 1, 1),
	SHELL_CMD_ARG(send_interval, NULL, HELP_SEND_INTERVAL, cmd_send_interval, 1, 1),
	SHELL_SUBCMD_SET_END
);

SHELL_CMD_REGISTER(lorawan, &sub_lorawan, "lorawan commands", NULL);

SHELL_COND_CMD_ARG_REGISTER(CONFIG_SHELL_START_OBSCURED, login, NULL,
			    "<password>", cmd_login, 2, 0);

SHELL_COND_CMD_REGISTER(CONFIG_SHELL_START_OBSCURED, logout, NULL,
			"Log out.", cmd_logout);

void dl_shell_cmd_exec(uint8_t len, const uint8_t *data)
{
	char cmd_buff[DL_SHELL_CMD_BUF_SIZE];
	char *shell_cmd;
	size_t cmd_len;
	int err;

	/* at least single character cmd requred after "shell " prefix */
	if (len < (strlen(DL_SHELL_CMD_PREFIX) + 1)) {
		return;
	}

	cmd_len = len < DL_SHELL_CMD_BUF_SIZE ? len : DL_SHELL_CMD_BUF_SIZE;
	strncpy(cmd_buff, data, cmd_len);
	cmd_buff[cmd_len] = '\0';

	shell_cmd = strstr(cmd_buff, DL_SHELL_CMD_PREFIX);
	if (shell_cmd == NULL) {
		return;
	}

	shell_cmd += strlen(DL_SHELL_CMD_PREFIX);

	LOG_INF("shell: execute cmd: '%s'", shell_cmd);

	err = shell_execute_cmd(NULL, shell_cmd);
	if (err) {
		LOG_ERR("Can't execute shell cmd: '%s', err: %d", shell_cmd, err);
	}
}

int init_shell(void)
{
	const struct device *dev;

	dev = DEVICE_DT_GET(DT_CHOSEN(zephyr_shell_uart));
	if (!device_is_ready(dev)) {
		LOG_ERR("Can't find shell device");
		return -ENODEV;
	}

	if (IS_ENABLED(CONFIG_SHELL_START_OBSCURED)) {
		login_init();
	}

	return 0;
}
```

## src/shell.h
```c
/*
 *
 * SPDX-License-Identifier: Apache-2.0
 */

#ifndef __HELIUM_METEO_SHELL_H__
#define __HELIUM_METEO_SHELL_H__

enum shell_cmd_event {
	SHELL_CMD_SEND_TIMER,
	SHELL_CMD_SEND_TIMER_GET,
};

#define DL_SHELL_CMD_BUF_SIZE 64
#define DL_SHELL_CMD_PREFIX "shell "
void dl_shell_cmd_exec(uint8_t len, const uint8_t *data);

typedef void (*shell_cmd_cb_t)(enum shell_cmd_event event, void *user_data);

int init_shell(void);
void shell_register_cb(shell_cmd_cb_t cb, void *);

#endif /* __HELIUM_METEO_SHELL_H__ */
```
